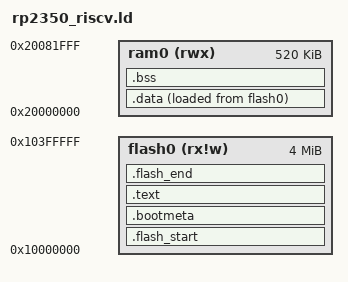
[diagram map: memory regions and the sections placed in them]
/*
 * This file was auto-generated by microzig
 *
 * Target CPU:  generic_rv32
 * Target Chip: RP2350
 */

ENTRY(microzig_main);

MEMORY
{
  flash0 (rx!w) : ORIGIN = 0x10000000, LENGTH = 0x00400000
  ram0   (rwx) : ORIGIN = 0x20000000, LENGTH = 0x00082000
}

SECTIONS
{
  .flash_start :
  {
    KEEP(*(microzig_flash_start))
  } > flash0

  .bootmeta :
  {
    __bootmeta_start__ = .;
    KEEP(*(.bootmeta))
    __bootmeta_end__ = .;
  } > flash0

  .text :
  {
     *(.text*)
  } > flash0

  .data :
  {
     microzig_data_start = .;
     *(.sdata*)
     *(.data*)
     *(.rodata*)
     microzig_data_end = .;
  } > ram0 AT> flash0

  .bss (NOLOAD) :
  {
      microzig_bss_start = .;
      *(.bss*)
      *(.sbss*)
      microzig_bss_end = .;
  } > ram0
  
  .flash_end :
  {
    microzig_flash_end = .;
  } > flash0

  microzig_data_load_start = LOADADDR(.data);
  PROVIDE(__global_pointer$ = microzig_data_start + 0x800);
}
